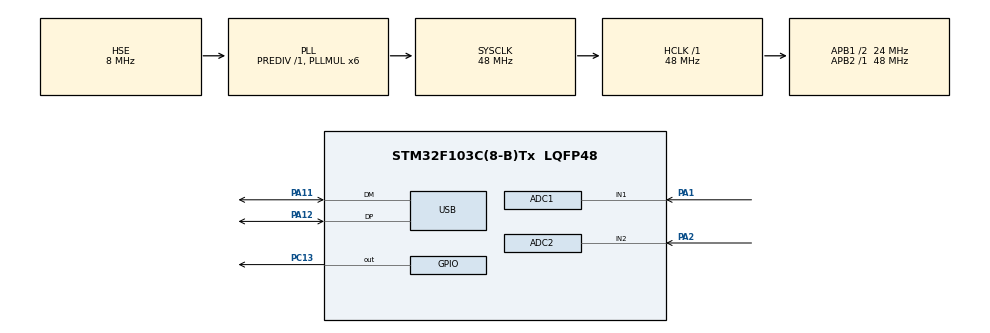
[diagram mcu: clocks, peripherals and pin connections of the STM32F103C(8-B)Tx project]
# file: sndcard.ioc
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ADC1.Channel-1\#ChannelRegularConversion=ADC_CHANNEL_1
ADC1.ContinuousConvMode=ENABLE
ADC1.EnableAnalogWatchDog=false
ADC1.EnableRegularConversion=ENABLE
ADC1.ExternalTrigConv=ADC_SOFTWARE_START
ADC1.InjNumberOfConversion=0
ADC1.NbrOfConversion=1
ADC1.NbrOfConversionFlag=1
ADC1.Rank-1\#ChannelRegularConversion=1
ADC1.SamplingTime-1\#ChannelRegularConversion=ADC_SAMPLETIME_1CYCLE_5
ADC1.master=1
ADC2.Channel-0\#ChannelRegularConversion=ADC_CHANNEL_2
ADC2.ContinuousConvMode=ENABLE
ADC2.NbrOfConversionFlag=1
ADC2.Rank-0\#ChannelRegularConversion=1
ADC2.SamplingTime-0\#ChannelRegularConversion=ADC_SAMPLETIME_1CYCLE_5
Mcu.Family=STM32F1
Mcu.Name=STM32F103C(8-B)Tx
Mcu.Package=LQFP48
NVIC.PriorityGroup=NVIC_PRIORITYGROUP_4
NVIC.USB_LP_CAN1_RX0_IRQn=true\:0\:0\:false\:false\:true\:false\:true
PA1.Signal=ADCx_IN1
PA11.Mode=Device
PA11.Signal=USB_DM
PA12.Mode=Device
PA12.Signal=USB_DP
PA13.Mode=Serial_Wire
PA13.Signal=SYS_JTMS-SWDIO
PA14.Mode=Serial_Wire
PA14.Signal=SYS_JTCK-SWCLK
PA2.Signal=ADCx_IN2
PC13-TAMPER-RTC.PinState=GPIO_PIN_SET
PC13-TAMPER-RTC.Signal=GPIO_Output
PD0-OSC_IN.Mode=HSE-External-Oscillator
PD0-OSC_IN.Signal=RCC_OSC_IN
PD1-OSC_OUT.Mode=HSE-External-Oscillator
PD1-OSC_OUT.Signal=RCC_OSC_OUT
ProjectManager.HeapSize=0x200
ProjectManager.StackSize=0x400
ProjectManager.TargetToolchain=MDK-ARM V5
RCC.ADCPresc=RCC_ADCPCLK2_DIV4
RCC.AHBFreq_Value=48000000
RCC.APB1CLKDivider=RCC_HCLK_DIV2
RCC.APB1Freq_Value=24000000
RCC.APB1TimFreq_Value=48000000
RCC.APB2Freq_Value=48000000
RCC.APB2TimFreq_Value=48000000
RCC.HCLKFreq_Value=48000000
RCC.PLLMUL=RCC_PLL_MUL6
RCC.SYSCLKFreq_VALUE=48000000
RCC.SYSCLKSource=RCC_SYSCLKSOURCE_PLLCLK
RCC.USBFreq_Value=48000000
SH.ADCx_IN1.0=ADC1_IN1,IN1
SH.ADCx_IN2.0=ADC2_IN2,IN2
USB_DEVICE.CLASS_NAME_FS=CDC
USB_DEVICE.VID=16313
USB_DEVICE.VirtualMode=Cdc
USB_DEVICE.VirtualModeFS=Cdc_FS
VP_USB_DEVICE_VS_USB_DEVICE_CDC_FS.Mode=CDC_FS
board=custom

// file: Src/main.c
/* USER CODE BEGIN Header */
/**
  ******************************************************************************
  * @file           : main.c
  * @brief          : Main program body
  ******************************************************************************
  * @attention
  *
  * <h2><center>&copy; Copyright (c) 2019 STMicroelectronics.
  * All rights reserved.</center></h2>
  *
  * This software component is licensed by ST under Ultimate Liberty license
  * SLA0044, the "License"; You may not use this file except in compliance with
  * the License. You may obtain a copy of the License at:
  *                             www.st.com/SLA0044
  *
  ******************************************************************************
  */
/* USER CODE END Header */

#include "main.h"
#include "adc.h"
#include "usb_device.h"
#include "gpio.h"

/* USER CODE BEGIN Includes */
//#include "usbd_cdc_if.h"
/* USER CODE END Includes */

void SystemClock_Config(void);
/* USER CODE BEGIN PFP */
uint32_t count;
uint32_t* adc_buf;
char* j;

/* USER CODE END PFP */

/* USER CODE BEGIN 0 */

//void HAL_ADC_ConvCpltCallback(ADC_HandleTypeDef* hadc)
//{
//  /* Prevent unused argument(s) compilation warning */
//	if(count>=1023) count = 0;
//	sprintf(j+count*4, "%d", *adc_buf);
//  /* NOTE : This function should not be modified. When the callback is needed,
//            function HAL_ADC_ConvCpltCallback must be implemented in the user file.
//   */
//}
/* USER CODE END 0 */

int main(void)
{
  /* USER CODE BEGIN 1 */
	//	int val;

  /* USER CODE END 1 */

  /* MCU Configuration--------------------------------------------------------*/

  /* Reset of all peripherals, Initializes the Flash interface and the Systick. */
  HAL_Init();

  /* Configure the system clock */
  SystemClock_Config();

  /* Initialize all configured peripherals */
  MX_GPIO_Init();
  MX_ADC1_Init();
  MX_USB_DEVICE_Init();
  MX_ADC2_Init();
  /* USER CODE BEGIN 2 */
	HAL_ADC_MspInit(&hadc1);
	HAL_ADC_MspInit(&hadc2);
	HAL_ADC_Start(&hadc1);
	HAL_ADC_Start(&hadc2);
  /* USER CODE END 2 */

  /* Infinite loop */
  while (1)
  {

  }
}

void SystemClock_Config(void)
{
  RCC_OscInitTypeDef RCC_OscInitStruct = {0};
  RCC_ClkInitTypeDef RCC_ClkInitStruct = {0};
  RCC_PeriphCLKInitTypeDef PeriphClkInit = {0};

  /** Initializes the CPU, AHB and APB busses clocks
  */
  RCC_OscInitStruct.OscillatorType = RCC_OSCILLATORTYPE_HSE;
  RCC_OscInitStruct.HSEState = RCC_HSE_ON;
  RCC_OscInitStruct.HSEPredivValue = RCC_HSE_PREDIV_DIV1;
  RCC_OscInitStruct.HSIState = RCC_HSI_ON;
  RCC_OscInitStruct.PLL.PLLState = RCC_PLL_ON;
  RCC_OscInitStruct.PLL.PLLSource = RCC_PLLSOURCE_HSE;
  RCC_OscInitStruct.PLL.PLLMUL = RCC_PLL_MUL6;
  if (HAL_RCC_OscConfig(&RCC_OscInitStruct) != HAL_OK)
  {
    Error_Handler();
  }
  /** Initializes the CPU, AHB and APB busses clocks
  */
  RCC_ClkInitStruct.ClockType = RCC_CLOCKTYPE_HCLK|RCC_CLOCKTYPE_SYSCLK
                              |RCC_CLOCKTYPE_PCLK1|RCC_CLOCKTYPE_PCLK2;
  RCC_ClkInitStruct.SYSCLKSource = RCC_SYSCLKSOURCE_PLLCLK;
  RCC_ClkInitStruct.AHBCLKDivider = RCC_SYSCLK_DIV1;
  RCC_ClkInitStruct.APB1CLKDivider = RCC_HCLK_DIV2;
  RCC_ClkInitStruct.APB2CLKDivider = RCC_HCLK_DIV1;

  if (HAL_RCC_ClockConfig(&RCC_ClkInitStruct, FLASH_LATENCY_1) != HAL_OK)
  {
    Error_Handler();
  }
  PeriphClkInit.PeriphClockSelection = RCC_PERIPHCLK_ADC|RCC_PERIPHCLK_USB;
  PeriphClkInit.AdcClockSelection = RCC_ADCPCLK2_DIV4;
  PeriphClkInit.UsbClockSelection = RCC_USBCLKSOURCE_PLL;
  if (HAL_RCCEx_PeriphCLKConfig(&PeriphClkInit) != HAL_OK)
  {
    Error_Handler();
  }
}

void Error_Handler(void)
{
}

/************************ (C) COPYRIGHT STMicroelectronics *****END OF FILE****/
